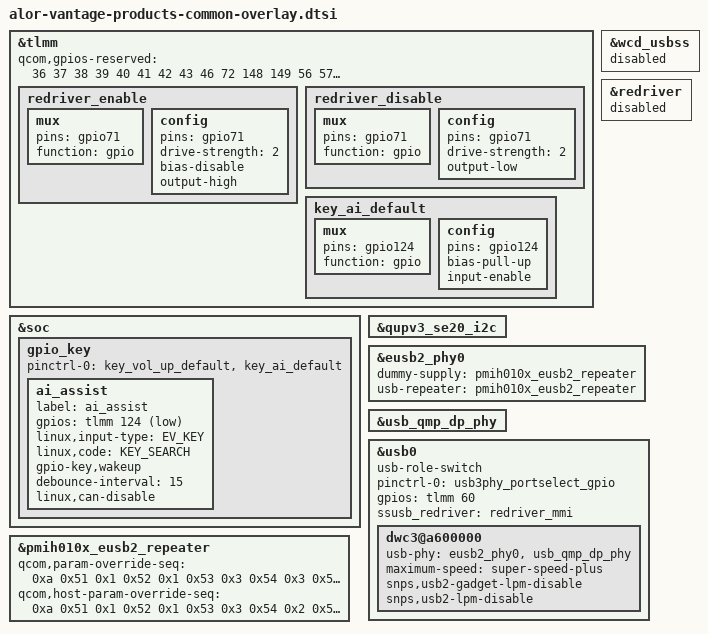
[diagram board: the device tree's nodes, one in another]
/* Copyright (c) 2025, The Linux Foundation. All rights reserved.
 *
 * This program is free software; you can redistribute it and/or modify
 * it under the terms of the GNU General Public License version 2 and
 * only version 2 as published by the Free Software Foundation.
 *
 * This program is distributed in the hope that it will be useful,
 * but WITHOUT ANY WARRANTY; without even the implied warranty of
 * MERCHANTABILITY or FITNESS FOR A PARTICULAR PURPOSE.  See the
 * GNU General Public License for more details.
 */

/*
   This file is used for all vantage products include prc, row, na etc.
*/

#include "alor-moto-common-overlay-base.dtsi"
#include "alor-moto-common-overlay.dtsi"
#include "alor-moto-common-charger.dtsi"
#include "alor-vantage-charger-overlay.dtsi"
#include "alor-vantage-haptics-overlay.dtsi"
#include "alor-vantage-sensors-overlay.dtsi"
#include "alor-vantage-touchscreen-thp-overlay.dtsi"
#include "alor-qrd-peach-vantage.dtsi"
#include "alor-vantage-thermal-overlay.dtsi"

&tlmm {
	/* remove gpio73/74/75 as they are used as camera LDO enable pin*/
	/* remove gpio40/41/42/43 as they are used as QFP SPI, which are accessed only by TEE */
	qcom,gpios-reserved = <36 37 38 39 40 41 42 43 46 72 148 149 56 57 58 59>;

	redriver_enable: redriver_enable {
		mux {
			pins = "gpio71";
			function = "gpio";
		};

		config {
			pins = "gpio71";
			drive-strength = <2>;
			bias-disable; /* NO PULL */
			output-high;
		};
	};
	redriver_disable: redriver_disable {
		mux {
			pins = "gpio71";
			function = "gpio";
		};

		config {
			pins = "gpio71";
			drive-strength = <2>;
			output-low;
		};
	};

	key_ai_default: key_ai_default {
		mux {
			pins = "gpio124";
			function = "gpio";
		};

		config {
			pins = "gpio124";
			bias-pull-up;
			input-enable;
		};
	};
};

&soc {
	gpio_key {
		pinctrl-names = "default";
		pinctrl-0 = <&key_vol_up_default>, <&key_ai_default>;

		ai_assist {
			label = "ai_assist";
			gpios = <&tlmm 124 GPIO_ACTIVE_LOW>;
			linux,input-type = <EV_KEY>;
			linux,code = <KEY_SEARCH>;
			gpio-key,wakeup;
			debounce-interval = <15>;
			linux,can-disable;
		};
	};
};

&wcd_usbss {
	status = "disabled";
};
&redriver {
	status = "disabled";
};

&qupv3_se20_i2c {
	status = "ok";
	#include "alor-vantage-usb-redriver.dtsi"
};

&eusb2_phy0 {
	dummy-supply = <&pmih010x_eusb2_repeater>;
	usb-repeater = <&pmih010x_eusb2_repeater>;
};

&usb_qmp_dp_phy {
	pinctrl-names = "unused";
};

&usb0 {
	usb-role-switch;
	pinctrl-names = "default";
	pinctrl-0 = <&usb3phy_portselect_gpio>;
	gpios = <&tlmm 60 0>;

	ssusb_redriver = <&redriver_mmi>;

	/delete-property/ qcom,wcd_usbss;

	dwc3@a600000 {
		usb-phy = <&eusb2_phy0>, <&usb_qmp_dp_phy>;
		maximum-speed = "super-speed-plus";
		snps,usb2-gadget-lpm-disable;
		snps,usb2-lpm-disable;
	};
};

&pmih010x_eusb2_repeater {
	qcom,param-override-seq =
		/* <value reg_offset> */
		/* Adjust HS trasmit amplitude */
		<0xa 0x51
		/* HS termination resistor */
		 0x1 0x52
		/* HS disconnect threshold */
		 0x1 0x53
		/* Squelch detection threshold */
		 0x3 0x54
		/* USB2 Tx slew rate */
		 0x3 0x55
		/* USB2 Rx Equalization */
		 0x0 0x56
		/* Tx pre-emphasis tuning */
		 0x3 0x57>;
	qcom,host-param-override-seq =
		/* <value reg_offset> */
		/* Adjust HS trasmit amplitude */
		<0xa 0x51
		/* HS termination resistor */
		 0x1 0x52
		/* HS disconnect threshold */
		 0x1 0x53
		/* Squelch detection threshold */
		 0x3 0x54
		/* USB2 Tx slew rate */
		 0x2 0x55
		/* USB2 Rx Equalization */
		 0x0 0x56
		/* Tx pre-emphasis tuning */
		 0x3 0x57>;
};
